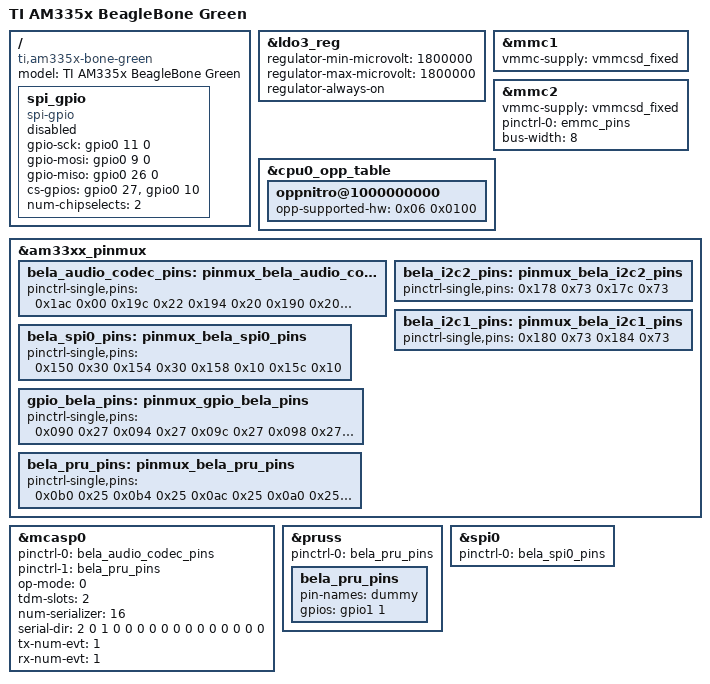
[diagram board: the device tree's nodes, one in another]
/*
 * Copyright (C) 2017 Henrik Langer henni19790@googlemail.com
 *
 * This program is free software; you can redistribute it and/or modify
 * it under the terms of the GNU General Public License version 2 as
 * published by the Free Software Foundation.
 */
/dts-v1/;

#include "am33xx.dtsi"
#include "am335x-bone-common.dtsi"
/* #include "am33xx-overlay-edma-fix.dtsi" */

/* pruss: pick one: */

/*
 * /etc/modprobe.d/pruss-blacklist.conf
 *
 * blacklist uio_pruss
 */

/* #include "am33xx-pruss-rproc.dtsi" */

/*
 * /etc/modprobe.d/pruss-blacklist.conf
 *
 * blacklist pruss
 * blacklist pruss_intc
 * blacklist pru-rproc
 */

#include "am33xx-pruss-uio.dtsi"

/ {
	model = "TI AM335x BeagleBone Green";
	compatible = "ti,am335x-bone-green", "ti,am335x-bone-black", "ti,am335x-bone", "ti,am33xx";

	/*
		Optional SW SPI interface to configure AD1938 codec of CTAG face2|4 Audio Card
	*/
	spi_gpio: spi_gpio {
		compatible = "spi-gpio";
		#address-cells = <1>;
		ranges;

		gpio-sck = <&gpio0 11 0>; 				//P8.32
		gpio-mosi = <&gpio0 9 0>;				//P8.33
		gpio-miso = <&gpio0 26 0>;				//P8.14
		cs-gpios = <&gpio0 27 0 &gpio0 10 0>; 	//P8.17 / P8.31
		num-chipselects = <2>;

		status = "disabled";
	};
};

&ldo3_reg {
	regulator-min-microvolt = <1800000>;
	regulator-max-microvolt = <1800000>;
	regulator-always-on;
};

&mmc1 {
	vmmc-supply = <&vmmcsd_fixed>;
};

&mmc2 {
	vmmc-supply = <&vmmcsd_fixed>;
	pinctrl-names = "default";
	pinctrl-0 = <&emmc_pins>;
	bus-width = <8>;
	status = "okay";
};

&cpu0_opp_table {
	/*
	 * All PG 2.0 silicon may not support 1GHz but some of the early
	 * BeagleBone Blacks have PG 2.0 silicon which is guaranteed
	 * to support 1GHz OPP so enable it for PG 2.0 on this board.
	 */
	oppnitro@1000000000 {
		opp-supported-hw = <0x06 0x0100>;
	};
};

&am33xx_pinmux {

	/* Pinmux for McASP0 (audio i/o) */
	bela_audio_codec_pins: pinmux_bela_audio_codec_pins {
		pinctrl-single,pins = <
			0x1ac 0x00 /* mcasp0_ahclkx, 		P9_25 | MODE0 | OUTPUT_PULLDOWN */
			0x19c 0x22 /* mcasp0_axr2, 			P9_28 | MODE2 | INPUT_PULLDOWN */
			0x194 0x20 /* mcasp0_fsx, 			P9_29 | MODE0 | INPUT_PULLDOWN */
			0x190 0x20 /* mcasp0_ahclk, 		P9_31 | MODE0 | INPUT_PULLDOWN */
			0x198 0x20 /* mcasp0_axr0, 			P9_30 | MODE0 | INPUT_PULLDOWN */
		>;
	};

	/* Pinmux for McSPI0 (analog i/o) */
	bela_spi0_pins: pinmux_bela_spi0_pins {
		pinctrl-single,pins = <
			0x150 0x30 /* spi0_sclk, 			P9_22 | MODE0 | INPUT_PULLUP */
			0x154 0x30 /* spi0_d0, 				P9_21 | MODE0 | INPUT_PULLUP */
			0x158 0x10 /* spi0_d1, 				P9_18 | MODE0 | OUTPUT_PULLUP */
			0x15c 0x10 /* spi0_cs0, 			P9_17 | MODE0 | OUTPUT_PULLUP */
		>;
	};

	/* Pinmux for GPIO (digital i/o) */
	gpio_bela_pins: pinmux_gpio_bela_pins {
		pinctrl-single,pins = <
			0x090 0x27 /* gpio2[2], 			P8_07 | MODE7 | INPUT_PULLDOWN */
			0x094 0x27 /* gpio2[3], 			P8_08 | MODE7 | INPUT_PULLDOWN */
			0x09c 0x27 /* gpio2[5], 			P8_09 | MODE7 | INPUT_PULLDOWN */
			0x098 0x27 /* gpio2[4], 			P8_10 | MODE7 | INPUT_PULLDOWN */
			0x034 0x27 /* gpio1[13],			P8_11 | MODE7 | INPUT_PULLDOWN */
			0x030 0x27 /* gpio2[13],			P8_12 | MODE7 | INPUT_PULLDOWN */
			0x078 0x27 /* gpio1[28],			P9_12 | MODE7 | INPUT_PULLDOWN */
			0x048 0x27 /* gpio1[18],			P9_14 | MODE7 | INPUT_PULLDOWN */
			0x03c 0x27 /* gpio1[15],			P8_15 | MODE7 | INPUT_PULLDOWN */
			0x038 0x27 /* gpio1[14], 			P8_16 | MODE7 | INPUT_PULLDOWN */
			0x04c 0x27 /* gpio1[19],			P9_16 | MODE7 | INPUT_PULLDOWN */
			0x08c 0x27 /* gpio2[1], 			P8_18 | MODE7 | INPUT_PULLDOWN */
			0x0e0 0x27 /* gpio2[22],			P8_27 | MODE7 | INPUT_PULLDOWN */
			0x0e8 0x27 /* gpio2[24],			P8_28 | MODE7 | INPUT_PULLDOWN */
			0x0e4 0x27 /* gpio2[23],			P8_29 | MODE7 | INPUT_PULLDOWN */
			0x0ec 0x27 /* gpio2[25],			P8_30 | MODE7 | INPUT_PULLDOWN */
		>;
	};

	/* Pinmux for PRU */
	bela_pru_pins: pinmux_bela_pru_pins {
		pinctrl-single,pins = <
			0x0b0 0x25 /* pr1_pru1_pru_r30_4, 	P8_41 | MODE5 | INPUT_PULLDOWN */
			0x0b4 0x25 /* pr1_pru1_pru_r30_5, 	P8_42 | MODE5 | INPUT_PULLDOWN */
			0x0ac 0x25 /* pr1_pru1_pru_r30_3, 	P8_44 | MODE5 | INPUT_PULLDOWN */
			0x0a0 0x25 /* pr1_pru1_pru_r30_0, 	P8_45 | MODE5 | INPUT_PULLDOWN */
			0x0a4 0x25 /* pr1_pru1_pru_r30_1, 	P8_46 | MODE5 | INPUT_PULLDOWN */
			0x0a8 0x25 /* pr1_pru1_pru_r30_2, 	P8_43 | MODE5 | INPUT_PULLDOWN */
			/* Is needed for pin multiplexing Bela button correctly */
			0x1a4 0x37 /* gpio3[19], 			P9_27 | MODE7 | INPUT_PULLUP */
		>;
	};

	/* Pinmux for tlv320aic3104 audio codec control */
	bela_i2c2_pins: pinmux_bela_i2c2_pins {
		pinctrl-single,pins = <
			0x178 0x73 /* i2c2_sda,				P9_20 | MODE3 | INPUT_PULLUP | SLEWCTRL_SLOW */
			0x17c 0x73 /* i2c2_scl, 			P9_19 | MODE3 | INPUT_PULLUP | SLECCTRL_SLOW */
		>;
	};

	/* Pinmux for i2c on Bela header */
	bela_i2c1_pins: pinmux_bela_i2c1_pins {
		pinctrl-single,pins = <
			0x180 0x73 /* i2c1_sda, 			P9_26 | MODE3 | INPUT_PULLUP | SLEWCTRL_SLOW */
			0x184 0x73 /* i2c1_scl,				P9_24 | MODE3 | INPUT_PULLUP | SLEWCTRL_SLOW */
		>;
	};
};

/* McASP config */
&mcasp0 {
	pinctrl-names = "default";
	pinctrl-0 = <&bela_audio_codec_pins>;
	pinctrl-1 = <&bela_pru_pins>;

	status = "okay";

	op-mode = <0>;	// MCASP_IIS_MODE
	tdm-slots = <2>;
	num-serializer = <16>;
	serial-dir = <  // 0: INACTIVE, 1: TX, 2: RX
		2 0 1 0
		0 0 0 0
		0 0 0 0
		0 0 0 0
	>;
	tx-num-evt = <1>;
	rx-num-evt = <1>;
};

/* PRU config */
&pruss {
	pinctrl-names = "default";
	pinctrl-0 = <&bela_pru_pins>;
	
	status = "okay";

	/* Workaround for uio_pruss.c on 4.4.62 to prevent "No Children" error */
	bela_pru_pins {
		pin-names = "dummy";
		gpios = <&gpio1 1 2>;
		#gpio-cells = <2>;
	};
};

&spi0 {
       pinctrl-names = "default";
       pinctrl-0 = <&bela_spi0_pins>;

       status = "okay";
};
